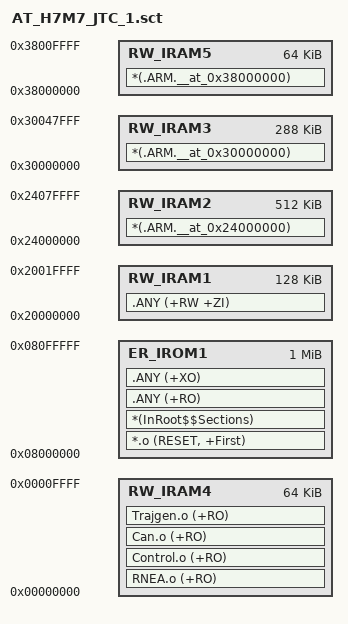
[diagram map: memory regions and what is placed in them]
; *************************************************************
; *** Scatter-Loading Description File generated by uVision ***
; *************************************************************

LR_IROM1 0x08000000 0x00100000  
{    ; load region size_region
  ER_IROM1 0x08000000 0x00100000  
  {  ; load address = execution address
   *.o (RESET, +First)
   *(InRoot$$Sections)
   .ANY (+RO)
   .ANY (+XO)
  }
   RW_IRAM1 0x20000000 0x00020000 ;DTCM RAM 128kB 
  {  ; RW data
    .ANY (+RW +ZI)
  }
  RW_IRAM2 0x24000000 0x00080000  ;AXIS SRAM 512kB
  {
    *(.ARM.__at_0x24000000)
  }
  RW_IRAM3 0x30000000 0x00048000 ;SRAM1 do SRAM3, max 288kB
  {
    *(.ARM.__at_0x30000000)
  }
  RW_IRAM4 0x00000000 0x00010000 ;ITCM RAM 64kB instrukje do szybkiego wykonania
  {
	RNEA.o (+RO)
	Control.o (+RO)
	Can.o (+RO)
	Trajgen.o (+RO)
    ; *(.ARM.__at_0x00000000)
  }
  RW_IRAM5 0x38000000 0x00010000  ;SRAM4 64kB
  {
	*(.ARM.__at_0x38000000)
  }
;  RW_IRAM5 0x38000000 0x00010000  ;SRAM4 64kB
;  {  ; RW data
;   .ANY (+RW +ZI)
;  }
}
